AUTOSAR XML (schema 314)
package /ComponentType
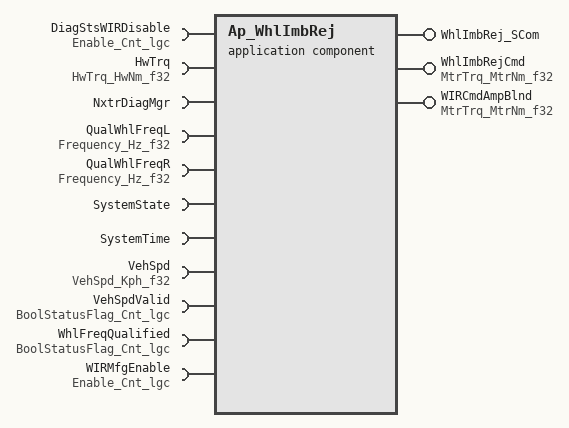
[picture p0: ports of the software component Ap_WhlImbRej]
  application software component type Ap_WhlImbRej
    provide port WhlImbRej_SCom: server-com-spec{operation=GetWIRInfo, queue-length=1}, provided-interface=WhlImbRej_SCom
    provide port WhlImbRejCmd: unqueued-sender-com-spec{data-element=MtrNm_f32, can-invalidate=false, init-value=D_ZERO_ULS_F32}, provided-interface=MtrTrq_MtrNm_f32
    provide port WIRCmdAmpBlnd: unqueued-sender-com-spec{data-element=MtrNm_f32, can-invalidate=false, init-value=D_ZERO_ULS_F32}, provided-interface=MtrTrq_MtrNm_f32
    11 x require port:
      DiagStsWIRDisable: unqueued-receiver-com-spec{data-element=Cnt_lgc, init-value=D_FALSE_CNT_LGC}, required-interface=Enable_Cnt_lgc
      HwTrq: unqueued-receiver-com-spec{data-element=HwNm_f32, init-value=D_ZERO_ULS_F32}, required-interface=HwTrq_HwNm_f32
      NxtrDiagMgr: required-com-specs=[GetNTCActive, GetNTCFailed, GetNTCStatus, SetNTCStatus], required-interface=NxtrDiagMgr
      QualWhlFreqL: unqueued-receiver-com-spec{data-element=Hz_f32, init-value=D_ZERO_ULS_F32}, required-interface=Frequency_Hz_f32
      QualWhlFreqR: unqueued-receiver-com-spec{data-element=Hz_f32, init-value=D_ZERO_ULS_F32}, required-interface=Frequency_Hz_f32
      SystemState: required-interface=SystemState
      SystemTime: required-interface=SystemTime
        required-com-specs:
          DtrmnElapsedTime_mS_u16
          DtrmnElapsedTime_mS_u32
          DtrmnElapsedTime_uS_u16
          DtrmnElapsedTime_uS_u32
          GetSystemTime_mS_u32
          GetSystemTime_uS_u32
      VehSpd: unqueued-receiver-com-spec{data-element=Kph_f32, init-value=D_ZERO_ULS_F32}, required-interface=VehSpd_Kph_f32
      VehSpdValid: unqueued-receiver-com-spec{data-element=Cnt_lgc, init-value=D_FALSE_CNT_LGC}, required-interface=BoolStatusFlag_Cnt_lgc
      WhlFreqQualified: unqueued-receiver-com-spec{data-element=Cnt_lgc, init-value=D_TRUE_CNT_LGC}, required-interface=BoolStatusFlag_Cnt_lgc
      WIRMfgEnable: unqueued-receiver-com-spec{data-element=Cnt_lgc, init-value=D_FALSE_CNT_LGC}, required-interface=Enable_Cnt_lgc
  internal behavior Ap_WhlImbRej_InternalBehavior: component=Ap_WhlImbRej
    4 x timing event:
      WhlImbRej_Init1_InitEvent: start-on-event=WhlImbRej_Init1, period=0
      TMT_WhlImbRej_Per1: mode-dependency=dependent-on-mode=[SystemState.Mode.DISABLE, SystemState.Mode.OFF, SystemState.Mode.WARMINIT], start-on-event=WhlImbRej_Per1, period=0.002
      TMT_WhlImbRej_Per2: mode-dependency=dependent-on-mode=[SystemState.Mode.DISABLE, SystemState.Mode.OFF, SystemState.Mode.WARMINIT], start-on-event=WhlImbRej_Per2, period=0.004
      TMT_WhlImbRej_Per3: mode-dependency=dependent-on-mode=SystemState.Mode.OPERATE, start-on-event=WhlImbRej_Per3, period=0.002
    operation invoked event OIT_WhlImbRej_SCom_GetWIRInfo_WhlImbRej_SCom_GetWIRInfo: start-on-event=WhlImbRej_SCom_GetWIRInfo, operation=WhlImbRej_SCom.GetWIRInfo
    port-api-options:
      enable-take-address=false, indirect-api=false, port=DiagStsWIRDisable
      enable-take-address=false, indirect-api=false, port=HwTrq
      enable-take-address=false, indirect-api=false, port=NxtrDiagMgr
      enable-take-address=false, indirect-api=false, port=QualWhlFreqL
      enable-take-address=false, indirect-api=false, port=QualWhlFreqR
      enable-take-address=false, indirect-api=false, port=SystemState
      enable-take-address=false, indirect-api=false, port=SystemTime
      enable-take-address=false, indirect-api=false, port=VehSpd
      enable-take-address=false, indirect-api=false, port=VehSpdValid
      enable-take-address=false, indirect-api=false, port=WhlFreqQualified
      enable-take-address=false, indirect-api=false, port=WhlImbRej_SCom
      enable-take-address=false, indirect-api=false, port=WhlImbRejCmd
      enable-take-address=false, indirect-api=false, port=WIRCmdAmpBlnd
      enable-take-address=false, indirect-api=false, port=WIRMfgEnable
    5 x runnable:
      WhlImbRej_Init1
      WhlImbRej_Per1
        8 x data read access:
          READ_DiagStsWIRDisable_Cnt_lgc: data-element=DiagStsWIRDisable.Cnt_lgc
          READ_HwTrq_HwNm_f32: data-element=HwTrq.HwNm_f32
          READ_QualWhlFreqL_Hz_f32: data-element=QualWhlFreqL.Hz_f32
          READ_QualWhlFreqR_Hz_f32: data-element=QualWhlFreqR.Hz_f32
          READ_VehSpd_Kph_f32: data-element=VehSpd.Kph_f32
          READ_VehSpdValid_Cnt_lgc: data-element=VehSpdValid.Cnt_lgc
          READ_WhlFreqQualified_Cnt_lgc: data-element=WhlFreqQualified.Cnt_lgc
          READ_WIRMfgEnable_Cnt_lgc: data-element=WIRMfgEnable.Cnt_lgc
        data write access WRITE_WhlImbRejCmd_MtrNm_f32: data-element=WhlImbRejCmd.MtrNm_f32
        data write access WRITE_WIRCmdAmpBlnd_MtrNm_f32: data-element=WIRCmdAmpBlnd.MtrNm_f32
        4 x sync call, all with timeout=0:
          SC_NxtrDiagMgr_SetNTCStatus: operation=NxtrDiagMgr.SetNTCStatus
          SC_SystemTime_DtrmnElapsedTime_mS_u16: operation=SystemTime.DtrmnElapsedTime_mS_u16
          SC_SystemTime_DtrmnElapsedTime_mS_u32: operation=SystemTime.DtrmnElapsedTime_mS_u32
          SC_SystemTime_GetSystemTime_mS_u32: operation=SystemTime.GetSystemTime_mS_u32
      WhlImbRej_Per2
      WhlImbRej_Per3
        data write access WRITE_WhlImbRejCmd_MtrNm_f32: data-element=WhlImbRejCmd.MtrNm_f32
      WhlImbRej_SCom_GetWIRInfo
  swc implementation Ap_WhlImbRej_Implementation: behavior=Ap_WhlImbRej_InternalBehavior
    code-descriptors:
      code Code: type=SRC
